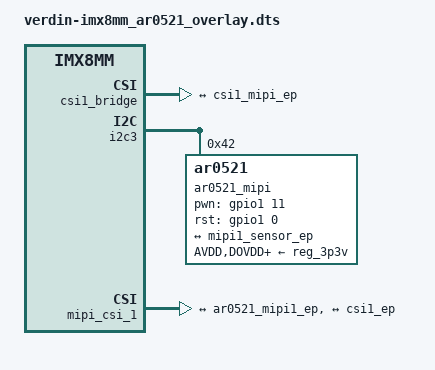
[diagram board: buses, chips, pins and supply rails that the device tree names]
// SPDX-License-Identifier: GPL-2.0-or-later OR MIT
/*
 * Copyright 2020-2022 Toradex
 */

// CSI Camera Module 5MP AR0521 orderable at Toradex and e-consystems.

/dts-v1/;
/plugin/;

#include <dt-bindings/clock/imx8mm-clock.h>
#include <dt-bindings/gpio/gpio.h>

/ {
	compatible = "toradex,verdin-imx8mm";
};

&csi1_bridge {
	fsl,mipi-mode;
	status = "okay";
	fsl,two-8bit-sensor-mode;
	cam-csi-bridge;

	port {
		csi1_ep: endpoint {
			remote-endpoint = <&csi1_mipi_ep>;
		};
	};
};

/* Verdin I2C_4_CSI */
&i2c3 {
	#address-cells = <1>;
	#size-cells = <0>;
	status = "okay";

	ar0521_mipi@42 {
		assigned-clocks = <&clk IMX8MM_CLK_CLKO1>;
		assigned-clock-parents = <&clk IMX8MM_CLK_24M>;
		assigned-clock-rates = <24000000>;
		AVDD-supply = <&reg_3p3v>;
		compatible = "ar0521";
		camera_mipi_lanes = <4>;
		cam-format-yuyv;
		clock-names = "csi_mclk";
		clocks = <&clk IMX8MM_CLK_CLKO1>;
		csi_id = <0>;
		DOVDD-supply = <&reg_3p3v>;
		DVDD-supply = <&reg_3p3v>;
		mclk = <24000000>;
		mclk_source = <0>;
		pinctrl-names = "default";
		pinctrl-0 = <&pinctrl_gpio5>, <&pinctrl_gpio6>;
		PVDD-supply = <&reg_3p3v>;
		pwn-gpios = <&gpio1 11 GPIO_ACTIVE_HIGH>;
		reg = <0x42>;
		rst-gpios = <&gpio1 0 GPIO_ACTIVE_HIGH>;
		status = "okay";

		port {
			ar0521_mipi1_ep: endpoint {
				remote-endpoint = <&mipi1_sensor_ep>;
			};
		};
	};
};

&mipi_csi_1 {
	status = "okay";

	port {
		#address-cells = <1>;
		#size-cells = <0>;

		mipi1_sensor_ep: endpoint@1 {
			csis-hs-settle = <13>;
			csis-clk-settle = <2>;
			csis-wclk;
			data-lanes = <4>;
			cam-format-change;
			reg = <1>;
			remote-endpoint = <&ar0521_mipi1_ep>;
		};

		csi1_mipi_ep: endpoint@2 {
			reg = <2>;
			remote-endpoint = <&csi1_ep>;
		};
	};
};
